# V32F20x_CM33 register map
File version: 1.0.3
CPU: CM33 r0p4, little endian, MPU, FPU, DSP, 3 interrupt priority bits, 8 SAU regions
Registers are 32-bit, read-write, reset 0x0 unless marked. A register's access mark holds for its fields unless they carry their own. Offsets are from the block's base; [hi:lo] are bit positions; {n}, {i} and the like mark numbered series.

## SYSCFGLP — SYSCFGLP Peripheral Interface
Base 0x40102000
Same registers: SEC_SYSCFGLP 0x50102000
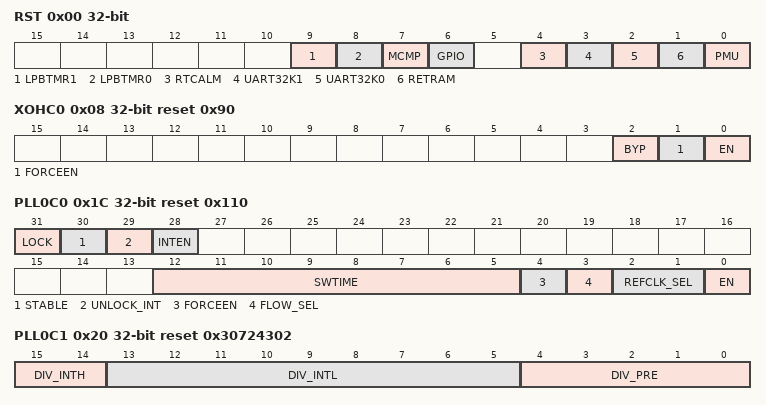
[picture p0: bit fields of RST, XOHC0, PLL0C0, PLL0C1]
0x00 RST — Peripheral reset control register
  [9] LPBTMR1 — Reset low-power basic timer 1
  [8] LPBTMR0 — Reset low-power basic timer 0
  [7] MCMP — Reset CMP in low-power domain
  [6] GPIO — Reset GPIO
  [4] RTCALM — Reset RTC alarm
  [3] UART32K1 — Reset UART32K1
  [2] UART32K0 — Reset UART32K0
  [1] RETRAM — Reset RET_RAM
  [0] PMU — Reset PMU controller
0x04 TRIMUNLOCK — TRIM register unlock register
  [0] UNLOCK
0x08 XOHC0 reset 0x90 — XOH control register 0
  [2] BYP — External active crystal input selectable signal high active
  [1] FORCEEN — Software force XOH wait stable gate cell enable high active
  [0] EN — Enable signal of XOH, high active.
0x1C PLL0C0 reset 0x110 — PLL0 control register 0
  [31] LOCK — PLL0 lock indication signal, high active.
  [30] STABLE — 1: PLL0 clock stable and not be gated
  [29] UNLOCK_INT — PLL0 unlock interrupt:
  [28] INTEN — PLL0 interrupt enable signal:
  [12:5] SWTIME — PLL0 clock output to chip wait time by software configure
  [4] FORCEEN — Software force PLL0 wait stable gate cell enable high active
  [3] FLOW_SEL — Select software or hardware flow control PLL0 clock output to chip
  [2:1] REFCLK_SEL — PLL0 reference clock select:
  [0] EN — Enable signal of PLL0, high active.
0x20 PLL0C1 reset 0x30724302 — PLL0 control register 1
  [15:14] DIV_INTH — This field which are used to set the first stage loop divider
  [13:5] DIV_INTL — This field used to set the second stage loop divider
  [4:0] DIV_PRE — Pre-divider of the reference clock
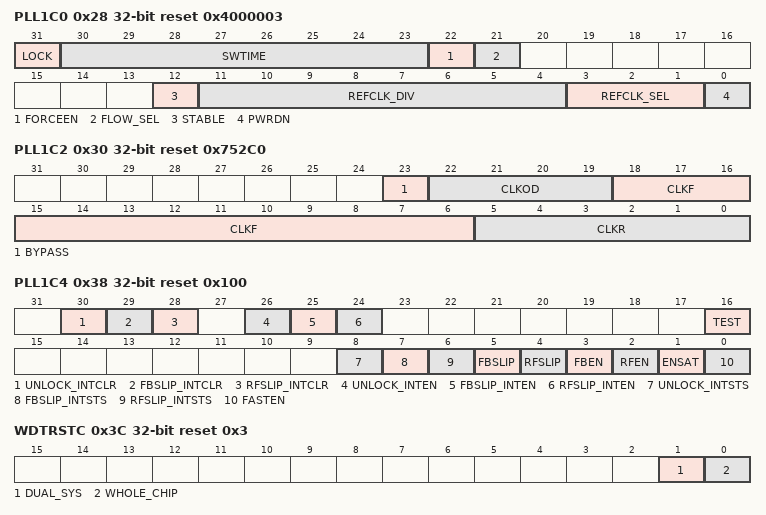
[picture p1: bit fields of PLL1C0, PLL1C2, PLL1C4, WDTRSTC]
0x28 PLL1C0 reset 0x4000003 — PLL1 control register 0
  [31] LOCK — PLL1 lock signal
  [30:23] SWTIME — PLL1 clock output to chip wait time by software configure
  [22] FORCEEN — Software force PLL1 wait stable gate cell enable high active
  [21] FLOW_SEL — Select software or hardware flow control PLL1 clock output to chip
  [12] STABLE — 1: PLL1 clock stable and not be gated
  [11:4] REFCLK_DIV — PLL1 reference clock divider control:
  [3:1] REFCLK_SEL — PLL1 reference clock select:
  [0] PWRDN — PLL1 power-down signal
0x2C PLL1C1 reset 0x1 — PLL1 control register 1
  [0] RESET — Reset signal, need follow the PLL1 reset sequence
0x30 PLL1C2 reset 0x752C0 — PLL1 control register 2
  [23] BYPASS — Reference to output bypass mode
  [22:19] CLKOD — A 4 bit bus that selects the values 1 to 16 for the post VCO divider OD default is 0 the PLL1 VCO output frequency 245
  [18:6] CLKF — A 13 bit bus that selects the values 1 to 8192 for the multiplication factor NF
  [5:0] CLKR — A 6 bit bus that selects the values 1 to 64 for the reference divider NR
0x34 PLL1C3 reset 0xEA5 — PLL1 control register 3
  [11:0] BWADJ — A 12 bit bus that selects the values 1 to 4096 for the bandwidth divider NB
0x38 PLL1C4 reset 0x100 — PLL1 control register 4
  [30] UNLOCK_INTCLR — PLL1 UNLOCK interrupt clear signa
  [29] FBSLIP_INTCLR — PLL1 FBSLIP interrupt clear signal
  [28] RFSLIP_INTCLR — PLL1 RFSLIP interrupt clear signal
  [26] UNLOCK_INTEN — PLL1 UNLOCK interrupt enable signal
  [25] FBSLIP_INTEN — PLL1 FBSLIP interrupt enable signal
  [24] RFSLIP_INTEN — PLL1 RFSLIP interrupt enable signal
  [16] TEST — The reference input drives all dividers cascaded one after the other for production testing
  [8] UNLOCK_INTSTS — PLL1 unlock interrupt status
  [7] FBSLIP_INTSTS — PLL1 fbslip interrupt status
  [6] RFSLIP_INTSTS — PLL1 rfslip interrupt status
  [5] FBSLIP — Feedback cycle slip output (CLKOUT frequency low)
  [4] RFSLIP — Reference cycle slip output CLKOUT frequency high
  [3] FBEN — Feedback divider NF count change enable output
  [2] RFEN — Reference divider NR count change enable output
  [1] ENSAT — Enables saturation behavior
  [0] FASTEN — Enables fast locking circuit
0x3C WDTRSTC reset 0x3 — WDT reset scope control register
  [1] DUAL_SYS — If this bit is 1 any of WDT0 WDT1 and WDT2 can reset CM33 and CM0 subsystem
  [0] WHOLE_CHIP — If this bit is 1 any of WDT0 WDT1 or WDT2 can reset whole chip that including CM33 CM0 subsystem and low power domain
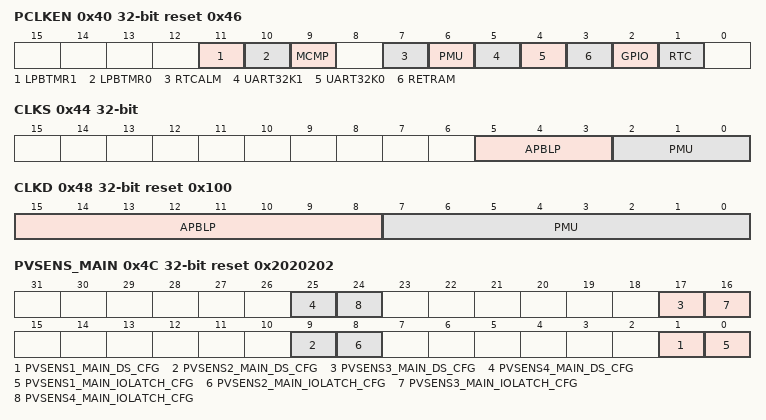
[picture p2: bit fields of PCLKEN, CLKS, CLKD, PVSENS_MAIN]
0x40 PCLKEN reset 0x46 — PCLK enable register
  [11] LPBTMR1 — Low power basic timer 1 LPBTMR1 PCLK enable signal
  [10] LPBTMR0 — Low power basic timer 0 LPBTMR0 PCLK enable signal
  [9] MCMP — CMP in low power domain PCLK and function clock enable signal
  [7] RTCALM — RTC alarm PCLK and function clock enable signal
  [6] PMU — PMU PCLK and function clock enable signal
  [5] UART32K1 — UART32K1 PCLK and function clock enable signal
  [4] UART32K0 — UART32K0 PCLK and function clock enable signal
  [3] RETRAM — RETRAM PCLK and function clock enable signal
  [2] GPIO — GPIO PCLK enable signal
  [1] RTC — RTC PCLK enable signal
0x44 CLKS — PMU and APB clock source selection register
  [5:3] APBLP — APB (in low-power domain) clock source select
  [2:0] PMU — PMU clock source select
0x48 CLKD reset 0x100 — PMU and APB clock divider control register
  [15:8] APBLP — APB (in low-power domain) clock divider control
  [7:0] PMU — PMU clock divider control
0x4C PVSENS_MAIN reset 0x2020202 — PVSENS in main domain IOLATCH and DS configuration register
  [8n-7] PVSENS{n}_MAIN_DS_CFG (n=1..4) — PVSENS{n} in main domain Deep standby signal 1
  [8n-8] PVSENS{n}_MAIN_IOLATCH_CFG (n=1..4) — PVSENS{n} in main domain Latch enable signal 1
0x50 CM0C reset 0x1 — CM0 control register
  [0] CM0_RST — CM0 reset signal default is reset status
0x54 ANALOCK — Analog lock register
  [0] UNLOCK — Analog lock register write 0xBEEFBEEF to lock analog control register write 0xFEEBFEEB to unlock
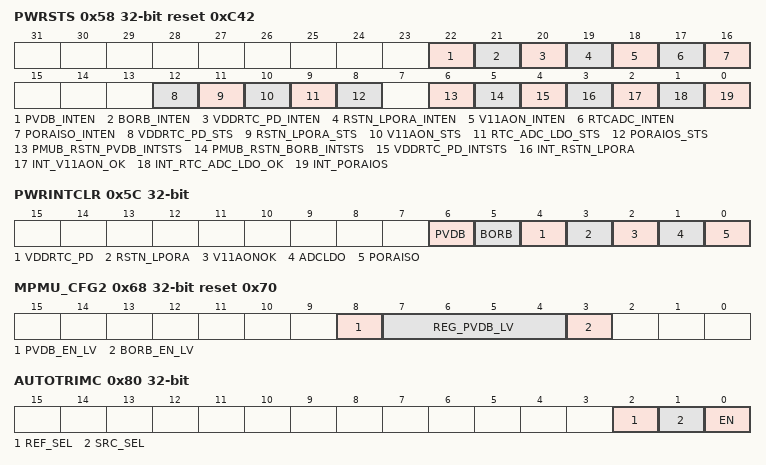
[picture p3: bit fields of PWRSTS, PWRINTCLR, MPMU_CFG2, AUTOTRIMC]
0x58 PWRSTS reset 0xC42 — Power status register
  [22] PVDB_INTEN — PVDB interrupt enable
  [21] BORB_INTEN — BORB interrupt enable
  [20] VDDRTC_PD_INTEN — VDDRTC_PD interrupt enable
  [19] RSTN_LPORA_INTEN — RSTN_LPORA interrupt enable
  [18] V11AON_INTEN — V11_AON interrupt enable
  [17] RTCADC_INTEN — RTC_ADC_LDO interrupt enable
  [16] PORAISO_INTEN — PORAISO interrupt enable
  [12] VDDRTC_PD_STS — VDDRTC PD status
  [11] RSTN_LPORA_STS — RSTN_LPORA status.
  [10] V11AON_STS — V11AON status.
  [9] RTC_ADC_LDO_STS — RTC LDOABS status.
  [8] PORAIOS_STS — RTC LDOABS status.
  [6] PMUB_RSTN_PVDB_INTSTS — PMUB_PVDB interrupt status.
  [5] PMUB_RSTN_BORB_INTSTS — PMUB_BORB interrupt status.
  [4] VDDRTC_PD_INTSTS — VDDRTCPD interrupt status
  [3] INT_RSTN_LPORA — RSTN_LPORA interrupt status.
  [2] INT_V11AON_OK — V11AON_OK interrupt status.
  [1] INT_RTC_ADC_LDO_OK — RTC LDOABS OK interrupt status.
  [0] INT_PORAIOS — VCC_PMU interrupt status VCC_PMU 1 is floating VCC_PMU 0 is OK
0x5C PWRINTCLR — Power status and interrupt clear register
  [6] PVDB — PVDB interrupt clear
  [5] BORB — BORB interrupt clear
  [4] VDDRTC_PD — VDDRTC_PD interrupt clear
  [3] RSTN_LPORA — RSTN_LPORA interrupt clear
  [2] V11AONOK — V11AON_OK interrupt clear
  [1] ADCLDO — ADCLDO interrupt clear
  [0] PORAISO — PORAISO interrupt clear
0x60 TRIM — IP in SYSCFGLP trim register
  [10:8] BORB_LV — This field is used to configure the output voltage of the DS_BORB
0x64 MPMU_CFG1 reset 0x1000 — Main PMU configure register 1
  [12:8] MLDOB_LV — This field is used to configure the output voltage of the MLDOB_CORE
0x68 MPMU_CFG2 reset 0x70 — Main PMU configure register 2
  [8] PVDB_EN_LV — The enable of PVDB, active high.
  [7:4] REG_PVDB_LV — The register to configure the threshold value of the PVDB
  [3] BORB_EN_LV — The enable signal of BORB, active high.
0x80 AUTOTRIMC — RCH auto trim control register
  [2] REF_SEL — Select the reference clock
  [1] SRC_SEL — Select the clock source to be trim
  [0] EN — RCH auto trim enable
0x84 AUTOTRIMU — RCH auto trim upper expect value register
  [18:0] UPPER_EXPT — The upper limit of expect count value for RCH auto trim
0x88 AUTOTRIML — RCH auto trim lower expect value register
  [18:0] LOWER_EXPT — The lower limit of expect count value for RCH auto trim
0x8C MPMU_AON_UPDATE — SYSCFGLP_MPMU_AON_UPDATE register
  [0] UPD — Write 0xAA55_55AA MPMU configuration in always on system will be updated
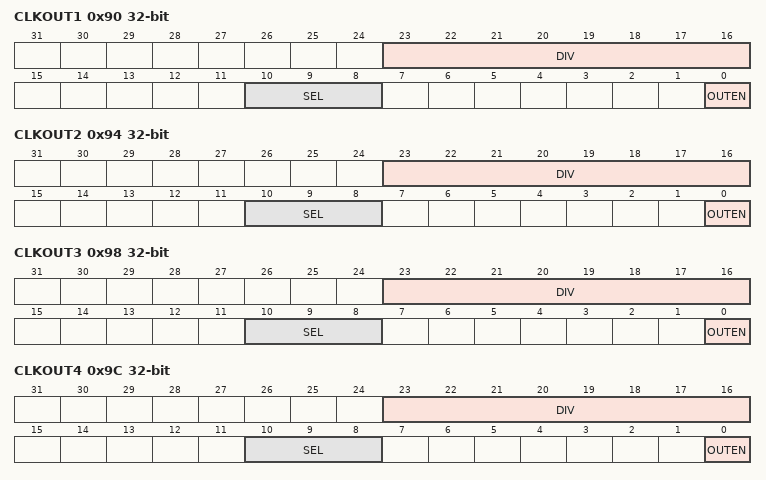
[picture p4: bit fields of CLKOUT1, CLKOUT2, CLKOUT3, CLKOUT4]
0x90 CLKOUT1 — Chip clock source output configure register 1
  [23:16] DIV — Microcontroller clock output (MCO1) divider value
  [10:8] SEL — Microcontroller clock output MCO1 source select signal
  [0] OUTEN — Microcontroller clock output (MCO1) enable signal
0x94 CLKOUT2 — Chip clock source output configure register 2
  [23:16] DIV — Microcontroller clock output (MCO2) divider value
  [10:8] SEL — Microcontroller clock output MCO2 source select signal
  [0] OUTEN — Microcontroller clock output (MCO2) enable signal
0x98 CLKOUT3 — Chip clock source output configure register 3
  [23:16] DIV — Microcontroller clock output MCO3 divider value
  [10:8] SEL — Microcontroller clock output MCO3 source select signal
  [0] OUTEN — Microcontroller clock output (MCO3) enable signal
0x9C CLKOUT4 — Chip clock source output configure register 4
  [23:16] DIV — Microcontroller clock output (MCO4) divider value
  [10:8] SEL — Microcontroller clock output MCO4 source select signal
  [0] OUTEN — Microcontroller clock output (MCO4) enable signal
0xA0 DBGC — Debug control register
  [8] WDT_DIS — WDT disable in debug mode control
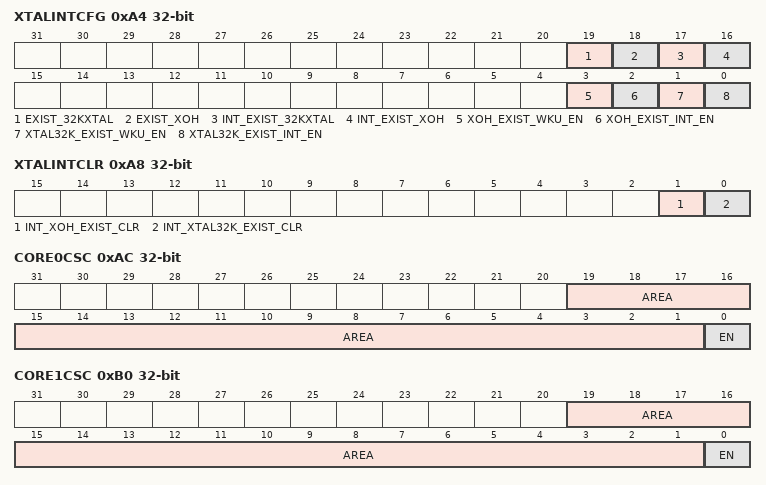
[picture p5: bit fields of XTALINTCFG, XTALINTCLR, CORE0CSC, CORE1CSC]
0xA4 XTALINTCFG — XTAL interrupt and wake up enable control register
  [19] EXIST_32KXTAL — 32K XTAL (XOL) exist status
  [18] EXIST_XOH — XOH exist status
  [17] INT_EXIST_32KXTAL — 32K XTAL disappear interrupt status
  [16] INT_EXIST_XOH — XOH exist interrupt status
  [3] XOH_EXIST_WKU_EN — XOH disappear wakeup enable
  [2] XOH_EXIST_INT_EN — XOH disappear interrupt enable
  [1] XTAL32K_EXIST_WKU_EN — 32K XTAL disappear wakeup enable
  [0] XTAL32K_EXIST_INT_EN — 32K XTAL disappear interrupt enable
0xA8 XTALINTCLR — XTAL interrupt clear register
  [1] INT_XOH_EXIST_CLR — Clear signal for XOH disappear interrupt
  [0] INT_XTAL32K_EXIST_CLR — Clear signal for 32K XTAL disappear interrupt
0xAC CORE0CSC — CM33 CORE0 code snooper control register
  [19:1] AREA — CM33 CORE0 code snooper area configure
  [0] EN — CM33 CORE0 code snooper enable
0xB0 CORE1CSC — CM33 CORE1 code snooper control register
  [19:1] AREA — CM33 CORE1 code snooper area configure
  [0] EN — CM33 CORE1 code snooper enable
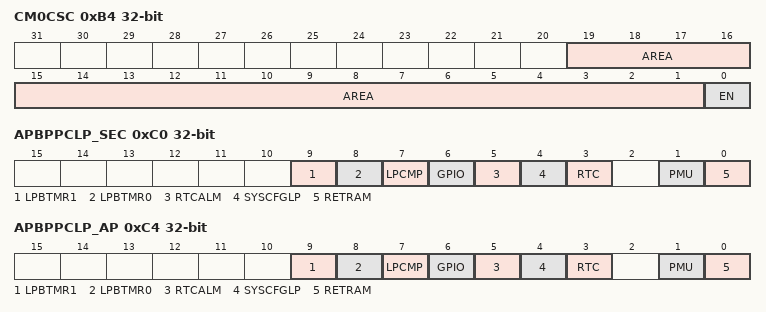
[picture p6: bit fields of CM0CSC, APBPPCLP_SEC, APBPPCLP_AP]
0xB4 CM0CSC — CM0 code snooper control register
  [19:1] AREA — CM0 code snooper area configure
  [0] EN — CM0 code snooper enable
0xC0 APBPPCLP_SEC — APBPPCLP security configure register
  [9] LPBTMR1 — Low power basic timer 1 LPBTMR1 security configure
  [8] LPBTMR0 — Low power basic timer 0 LPBTMR0 security configure
  [7] LPCMP — Low-power CMP security configure
  [6] GPIO — GPIO security configure
  [5] RTCALM — RTC alarm security configure
  [4] SYSCFGLP — SYSCFGLP security configure
  [3] RTC — RTC security configure
  [1] PMU — PMU security configure
  [0] RETRAM — RETRAM security configure
0xC4 APBPPCLP_AP — APBPPCLP access permission configure register
  [9] LPBTMR1 — Low power basic timer 1 LPBTMR1 access permission configure
  [8] LPBTMR0 — Low power basic timer 0 LPBTMR0 access permission configure
  [7] LPCMP — Low-power CMP access permission configure
  [6] GPIO — GPIO access permission configure
  [5] RTCALM — RTC alarm access permission configure
  [4] SYSCFGLP — SYSCFGLP access permission configure
  [3] RTC — RTC access permission configure
  [1] PMU — PMU access permission configure
  [0] RETRAM — RETRAM access permission configure
0xC8 APBPPCLP_RESP — APBPPCLP security error response configure register
  [0] RESP — APBPPCLP master security error response configure
0xE0 CORECFG reset 0x10000 — Core configure register
0xF0 REVID ro — Version ID register
  [31:0] REV_ID — version ID register
